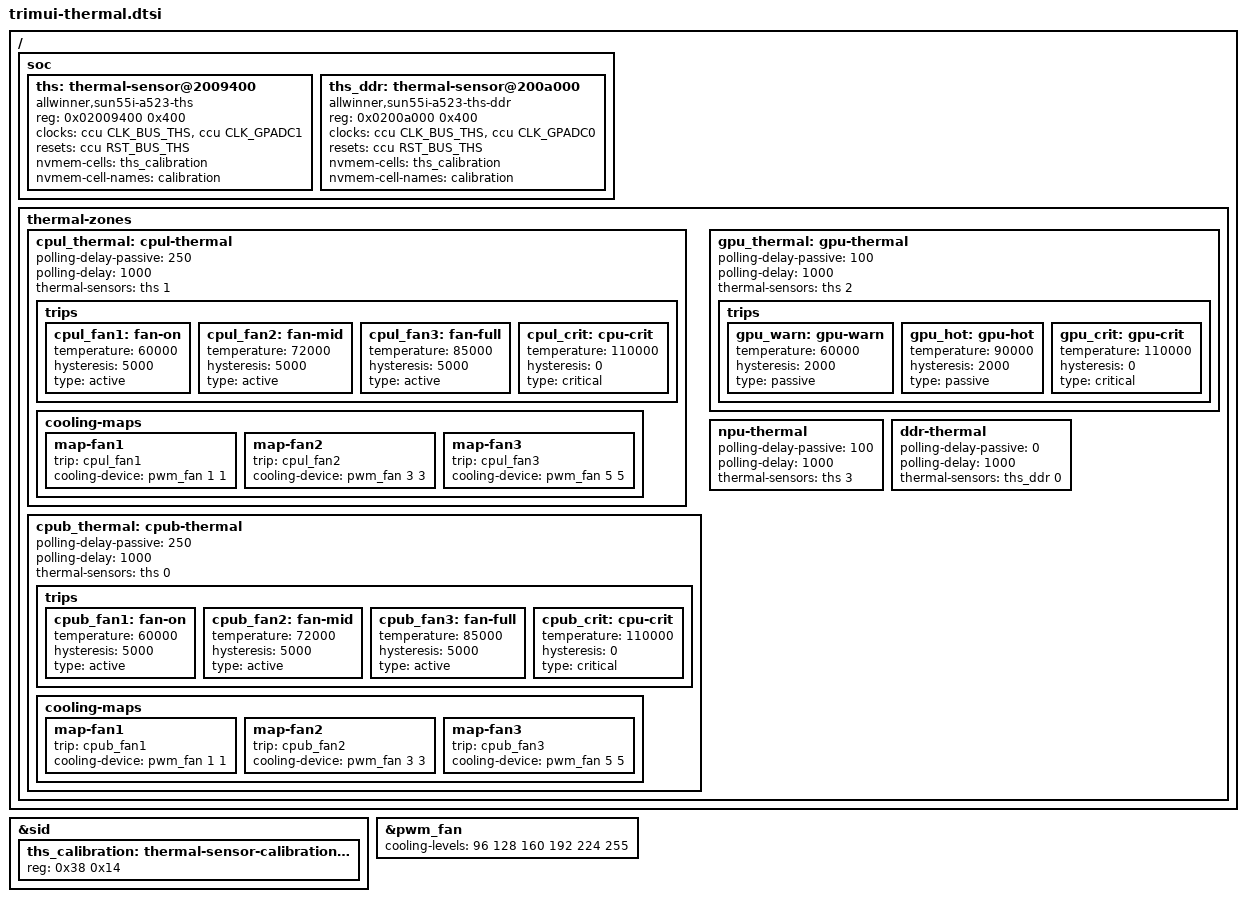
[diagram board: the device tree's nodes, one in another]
// SPDX-License-Identifier: (GPL-2.0-only OR MIT)
// Copyright (C) 2026 Midgy BALON
/*
 * A523 thermal — THS sensors + thermal-zones + active pwm-fan cooling.
 *
 * The THS *driver* is adopted from ut-slayer (kernel/patches/0021-0023,
 * allwinner,sun55i-a523-ths + -ths-ddr). Their SoC-dtsi patch (0087/0089)
 * doesn't apply to v7.2's shifted context, so we express the same nodes here
 * as board-level additions (THS via /soc, the calibration cell via &sid, the
 * zones + our pwm-fan cooling-maps). Node/zone/trip values are transcribed from
 * ut-slayer (BSP-derived); trip temps VERIFY/tune on hardware.
 *
 * Enable by `#include`ing this from the board DTS (needs the 0021-0023 patches +
 * CONFIG_SUN8I_THERMAL + CONFIG_THERMAL_GOV_*). The fan map hooks the pwm-fan on
 * the cpu-hot (90 C) trips; with the CPUs' dynamic-power-coefficient (see
 * trimui-cpu-opp.dtsi) IPA can also throttle cpufreq. See docs/THERMAL-DVFS-NOTES.md.
 */

#include <dt-bindings/thermal/thermal.h>

/* THS calibration lives in the SID efuse (0x38, 20 bytes). */
&sid {
	#address-cells = <1>;
	#size-cells = <1>;

	ths_calibration: thermal-sensor-calibration@38 {
		reg = <0x38 0x14>;
	};
};

/ {
	soc {
		ths: thermal-sensor@2009400 {
			compatible = "allwinner,sun55i-a523-ths";
			reg = <0x02009400 0x400>;
			clocks = <&ccu CLK_BUS_THS>, <&ccu CLK_GPADC1>;
			clock-names = "bus", "mod";
			resets = <&ccu RST_BUS_THS>;
			nvmem-cells = <&ths_calibration>;
			nvmem-cell-names = "calibration";
			#thermal-sensor-cells = <1>;
		};

		ths_ddr: thermal-sensor@200a000 {
			compatible = "allwinner,sun55i-a523-ths-ddr";
			reg = <0x0200a000 0x400>;
			clocks = <&ccu CLK_BUS_THS>, <&ccu CLK_GPADC0>;
			clock-names = "bus", "mod";
			resets = <&ccu RST_BUS_THS>;
			nvmem-cells = <&ths_calibration>;
			nvmem-cell-names = "calibration";
			#thermal-sensor-cells = <1>;
		};
	};

	thermal-zones {
		cpul_thermal: cpul-thermal {
			polling-delay-passive = <250>;
			polling-delay = <1000>;
			thermal-sensors = <&ths 1>;	/* little cluster */

			trips {
				/*
				 * Active fan ramp. The fan spins from 60 C and steps up
				 * with temperature; the pwm for each state is set in the
				 * &pwm_fan cooling-levels override below (state 1 = 50%).
				 * (A passive/IPA DVFS trip returns once the CPU-CCU
				 * cpufreq driver is back in the build.)
				 */
				cpul_fan1: fan-on   { temperature = <60000>;  hysteresis = <5000>; type = "active"; };
				cpul_fan2: fan-mid  { temperature = <72000>;  hysteresis = <5000>; type = "active"; };
				cpul_fan3: fan-full { temperature = <85000>;  hysteresis = <5000>; type = "active"; };
				cpul_crit: cpu-crit { temperature = <110000>; hysteresis = <0>;    type = "critical"; };
			};

			cooling-maps {
				map-fan1 { trip = <&cpul_fan1>; cooling-device = <&pwm_fan 1 1>; };	/* ~50% */
				map-fan2 { trip = <&cpul_fan2>; cooling-device = <&pwm_fan 3 3>; };	/* ~75% */
				map-fan3 { trip = <&cpul_fan3>; cooling-device = <&pwm_fan 5 5>; };	/* 100% */
			};
		};

		cpub_thermal: cpub-thermal {
			polling-delay-passive = <250>;
			polling-delay = <1000>;
			thermal-sensors = <&ths 0>;	/* big cluster (the hot one) */

			trips {
				cpub_fan1: fan-on   { temperature = <60000>;  hysteresis = <5000>; type = "active"; };
				cpub_fan2: fan-mid  { temperature = <72000>;  hysteresis = <5000>; type = "active"; };
				cpub_fan3: fan-full { temperature = <85000>;  hysteresis = <5000>; type = "active"; };
				cpub_crit: cpu-crit { temperature = <110000>; hysteresis = <0>;    type = "critical"; };
			};

			cooling-maps {
				map-fan1 { trip = <&cpub_fan1>; cooling-device = <&pwm_fan 1 1>; };	/* ~50% */
				map-fan2 { trip = <&cpub_fan2>; cooling-device = <&pwm_fan 3 3>; };	/* ~75% */
				map-fan3 { trip = <&cpub_fan3>; cooling-device = <&pwm_fan 5 5>; };	/* 100% */
			};
		};

		gpu_thermal: gpu-thermal {
			polling-delay-passive = <100>;
			polling-delay = <1000>;
			thermal-sensors = <&ths 2>;

			trips {
				gpu_warn: gpu-warn { temperature = <60000>; hysteresis = <2000>; type = "passive"; };
				gpu_hot: gpu-hot { temperature = <90000>; hysteresis = <2000>; type = "passive"; };
				gpu_crit: gpu-crit { temperature = <110000>; hysteresis = <0>; type = "critical"; };
			};
		};

		npu-thermal {
			polling-delay-passive = <100>;
			polling-delay = <1000>;
			thermal-sensors = <&ths 3>;
		};

		ddr-thermal {
			polling-delay-passive = <0>;
			polling-delay = <1000>;
			thermal-sensors = <&ths_ddr 0>;
		};
	};
};

/*
 * Fan duty curve. Each cooling-levels entry maps a cooling STATE (index) to a
 * pwm value (0-255); the thermal-zone cooling-maps above pick the state per trip.
 *
 * The stock board curve started state 1 at pwm 1, which is far too weak to spin
 * the fan (seen on HW: emulated 95 C -> state 1 -> pwm 1 -> fan did not move).
 *
 * state 0 is a non-zero ALWAYS-ON FLOOR (~37%) rather than off: the panel can't
 * yet be used as a power indicator, so a quietly-spinning fan is how you tell the
 * device is on when the SoC is cool. It then ramps to 100%:
 *   state 0 = 96 (~37% floor), 1 = 128 (~50%), 2 = 160 (~63%), 3 = 192 (~75%),
 *   4 = 224 (~88%), 5 = 255 (100%).
 * 96 is at/under this fan's stiction threshold from a dead stop, so a boot
 * one-shot (fan-boot-chirp.service) kicks the fan to 100% for ~3s at boot to give
 * an unmistakable power-on signal. HW note (2026-10-16): on our unit 37% did NOT
 * reliably sustain spin once the kick released, so the boot chirp is the reliable
 * "it's on" signal; tune this floor UP toward the measured quiet-sustain duty, and
 * confirm each step spins via `echo <mC> > .../thermal_zoneN/emul_temp`.
 */
&pwm_fan {
	cooling-levels = <96 128 160 192 224 255>;
};
